# ATmega1284RFR2 register map
Vendor: Atmel; File version: 1.0
CPU: other r0p0, little endian, no MPU, no FPU, 4 interrupt priority bits
Registers are 8-bit, read-write, reset 0x0 unless marked. A register's access mark holds for its fields unless they carry their own. Offsets are from the block's base; [hi:lo] are bit positions; 'fields as' and 'values as' point back to an identical list.

## PORTE — I/O Port
Base 0x0080002C
0x00 PINE — Port E Input Pins Address
0x01 DDRE — Port E Data Direction Register
0x02 PORTE — Port E Data Register

## PORTF — I/O Port
Base 0x0080002F
0x00 PINF — Port F Input Pins Address
0x01 DDRF — Port F Data Direction Register
0x02 PORTF — Port F Data Register

## PORTG — I/O Port
Base 0x00800032
0x00 PING — Port G Input Pins Address
0x01 DDRG — Port G Data Direction Register
0x02 PORTG — Port G Data Register

## PWRCTRL — Power Controller
Base 0x00800055
0x00 MCUCR — MCU Control Register
  [4] PUD — Pull-up Disable
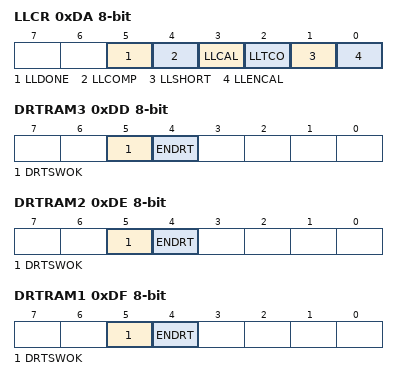
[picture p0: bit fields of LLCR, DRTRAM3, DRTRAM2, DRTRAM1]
0xDA LLCR — Low Leakage Voltage Regulator Control Register
  [5] LLDONE — Calibration Done
  [4] LLCOMP — Comparator Output
  [3] LLCAL — Calibration Active
  [2] LLTCO — Temperature Coefficient of Current Source
  [1] LLSHORT — Short Lower Calibration Circuit
  [0] LLENCAL — Enable Automatic Calibration
0xDB LLDRL — Low Leakage Voltage Regulator Data Register (Low-Byte)
  [3:0] LLDRL — Low-Byte Data Register Bits
    0=CALIBRATION_LIMIT_FOR_FAST_PROCESS_CORNER_HIGH_OUTPUT_VOLTAGE; 8=CALIBRATION_LIMIT_FOR_SLOW_PROCESS_CORNER_LOW_OUTPUT_VOLTAGE
0xDC LLDRH — Low Leakage Voltage Regulator Data Register (High-Byte)
  [4:0] LLDRH — High-Byte Data Register Bits
    0=CALIBRATION_LIMIT_FOR_FAST_PROCESS_CORNER_HIGH_OUTPUT_VOLTAGE; 16=CALIBRATION_LIMIT_FOR_SLOW_PROCESS_CORNER_LOW_OUTPUT_VOLTAGE
0xDD DRTRAM3 — Data Retention Configuration Register #3
  [5] DRTSWOK — DRT Switch OK
  [4] ENDRT — Enable SRAM Data Retention
0xDE DRTRAM2 — Data Retention Configuration Register #2
  [5] DRTSWOK — DRT Switch OK
  [4] ENDRT — Enable SRAM Data Retention
0xDF DRTRAM1 — Data Retention Configuration Register #1
  [5] DRTSWOK — DRT Switch OK
  [4] ENDRT — Enable SRAM Data Retention
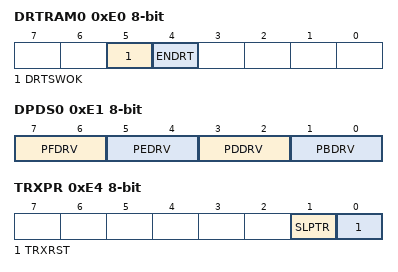
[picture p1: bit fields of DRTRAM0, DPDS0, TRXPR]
0xE0 DRTRAM0 — Data Retention Configuration Register #0
  [5] DRTSWOK — DRT Switch OK
  [4] ENDRT — Enable SRAM Data Retention
0xE1 DPDS0 — Port Driver Strength Register 0
  [all] fields
    0=PAD_IO_2MA (2 mA); 1=PAD_IO_4MA (4 mA); 2=PAD_IO_6MA (6 mA); 3=PAD_IO_8MA (8 mA)
  [7:6] PFDRV — Driver Strength Port F
  [5:4] PEDRV — Driver Strength Port E
  [3:2] PDDRV — Driver Strength Port D
  [1:0] PBDRV — Driver Strength Port B
0xE2 DPDS1 — Port Driver Strength Register 1
  [1:0] PGDRV — Driver Strength Port G
    values as the fields of DPDS0
0xE4 TRXPR — Transceiver Pin Register
  [1] SLPTR — Multi-purpose Transceiver Control Bit
  [0] TRXRST — Force Transceiver Reset

## SPI — Serial Peripheral Interface
Base 0x0080004C
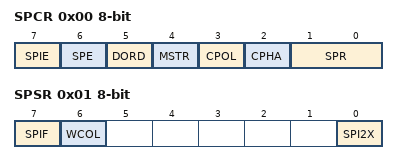
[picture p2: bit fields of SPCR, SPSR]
0x00 SPCR — SPI Control Register
  [7] SPIE — SPI Interrupt Enable
  [6] SPE — SPI Enable
  [5] DORD — Data Order
  [4] MSTR — Master/Slave Select
  [3] CPOL — Clock polarity
    0=RISING_LEADING_EDGE_FALLING_TRAILING_EDGE; 1=FALLING_LEADING_EGDE_RISING_TRAILING_EDGE (Falling (Leading Edge), Rising (Trailing Edge))
  [2] CPHA — Clock Phase
    0=SAMPLE_LEADING_EDGE_SETUP_TRAILING_EDGE; 1=SETUP_LEADING_EDGE_SAMPLE_TRAILING_EDGE
  [1:0] SPR — SPI Clock Rate Select 1 and 0
    0=FOSC_4_FOSC_2_SPI2X_0_1; 1=FOSC_16_FOSC_8_SPI2X_0_1; 2=FOSC_64_FOSC_32_SPI2X_0_1; 3=FOSC_128_FOSC_64_SPI2X_0_1
0x01 SPSR — SPI Status Register (read-only for debugger)
  [7] SPIF — SPI Interrupt Flag
  [6] WCOL — Write Collision Flag
  [0] SPI2X — Double SPI Speed Bit
0x02 SPDR — SPI Data Register (write-only for debugger)

## TC0 — Timer/Counter, 8-bit
Base 0x00800035
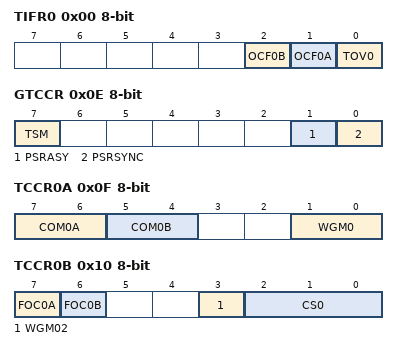
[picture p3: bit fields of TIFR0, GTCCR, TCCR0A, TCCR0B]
0x00 TIFR0 — Timer/Counter0 Interrupt Flag Register (read-only for debugger)
  [2] OCF0B — Timer/Counter0 Output Compare B Match Flag
  [1] OCF0A — Timer/Counter0 Output Compare A Match Flag
  [0] TOV0 — Timer/Counter0 Overflow Flag
0x0E GTCCR — General Timer/Counter Control Register
  [7] TSM — Timer/Counter Synchronization Mode
  [1] PSRASY — Prescaler Reset Timer/Counter2
  [0] PSRSYNC — Prescaler Reset for Synchronous Timer/Counters
0x0F TCCR0A — Timer/Counter0 Control Register A
  [7:6] COM0A — Compare Match Output A Mode
    0=NORMAL_PORT_OPERATION_OC0A_DISCONNECTED; 1=TOGGLE_OC0A_ON_COMPARE_MATCH; 2=CLEAR_OC0A_ON_COMPARE_MATCH; 3=SET_OC0A_ON_COMPARE_MATCH
  [5:4] COM0B — Compare Match Output B Mode
    0=NORMAL_PORT_OPERATION_OC0B_DISCONNECTED; 1=TOGGLE_OC0B_ON_COMPARE_MATCH; 2=CLEAR_OC0B_ON_COMPARE_MATCH; 3=SET_OC0B_ON_COMPARE_MATCH
  [1:0] WGM0 — Waveform Generation Mode
    0=NORMAL_MODE_OF_OPERATION; 1=PWM_PHASE_CORRECT_TOP_0XFF; 2=CTC_TOP_OCRA; 3=FAST_PWM_TOP_0XFF
0x10 TCCR0B — Timer/Counter0 Control Register B
  [7] FOC0A — Force Output Compare A
  [6] FOC0B — Force Output Compare B
  [3] WGM02
  [2:0] CS0 — Clock Select
    0=NO_CLOCK_SOURCE_TIMER_COUNTER0_STOPPED; 1=CLK_IO_1_NO_PRESCALING; 2=CLK_IO_8_FROM_PRESCALER; 3=CLK_IO_64_FROM_PRESCALER; 4=CLK_IO_256_FROM_PRESCALER; 5=CLK_IO_1024_FROM_PRESCALER; 6=EXTERNAL_CLOCK_SOURCE_ON_T0_PIN_CLOCK_ON_FALLING_EDGE; 7=EXTERNAL_CLOCK_SOURCE_ON_T0_PIN_CLOCK_ON_RISING_EDGE
0x11 TCNT0 — Timer/Counter0 Register
0x12 OCR0A — Timer/Counter0 Output Compare Register
0x13 OCR0B — Timer/Counter0 Output Compare Register B
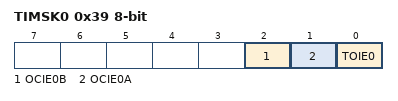
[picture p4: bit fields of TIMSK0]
0x39 TIMSK0 — Timer/Counter0 Interrupt Mask Register
  [2] OCIE0B — Timer/Counter0 Output Compare Match B Interrupt Enable
  [1] OCIE0A — Timer/Counter0 Output Compare Match A Interrupt Enable
  [0] TOIE0 — Timer/Counter0 Overflow Interrupt Enable
